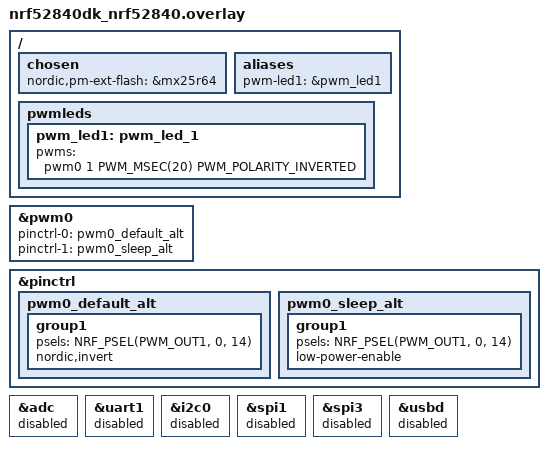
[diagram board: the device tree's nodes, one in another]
/*
 * Copyright (c) 2025 Nordic Semiconductor ASA
 *
 * SPDX-License-Identifier: LicenseRef-Nordic-5-Clause
 */

/ {
	chosen {
		nordic,pm-ext-flash = &mx25r64;
	};

	aliases{
		pwm-led1 = &pwm_led1;
	};

	pwmleds {
		pwm_led1: pwm_led_1 {
			pwms = <&pwm0 1 PWM_MSEC(20) PWM_POLARITY_INVERTED>;
		};
	};
};

&pwm0 {
	pinctrl-0 = <&pwm0_default_alt>;
	pinctrl-1 = <&pwm0_sleep_alt>;
	pinctrl-names = "default", "sleep";
};

&pinctrl {
	pwm0_default_alt: pwm0_default_alt {
		group1 {
			psels = <NRF_PSEL(PWM_OUT1, 0, 14)>;
			nordic,invert;
		};
	};

	pwm0_sleep_alt: pwm0_sleep_alt {
		group1 {
			psels = <NRF_PSEL(PWM_OUT1, 0, 14)>;
			low-power-enable;
		};
	};
};

/* Disable unused peripherals to reduce power consumption */
&adc {
	status = "disabled";
};

&uart1 {
	status = "disabled";
};

&i2c0 {
	status = "disabled";
};

&spi1 {
	status = "disabled";
};

&spi3 {
	status = "disabled";
};

&usbd {
	status = "disabled";
};
